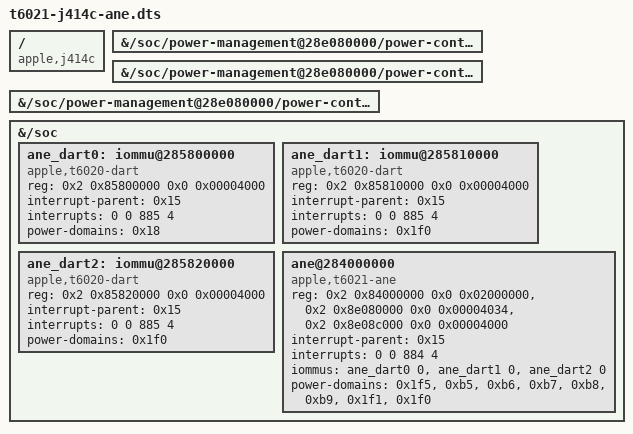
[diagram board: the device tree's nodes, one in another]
// SPDX-License-Identifier: GPL-2.0+ OR MIT
/*
 * Board overlay for jw14m2-linux (J414c / T6021, M2 Max): enable the ANE
 * engine, its three DARTs, and attach the ANE genpd chain the stock DTB
 * already carries (pmgr+0x4000: ane_td@4008 -> ane_base@4010 -> ane_set1..
 * set4@4018-4030, plus ane_cpu@2e0). Applied with fdtoverlay onto the
 * stock modules DTB; boot.bin is rebuilt with update-m1n1.
 *
 * Provenance (receipts 2026-09-18-t6021-engine-layout-mined,
 * 2026-09-18-h14-rtkit-port-phase1, 2026-09-18-h14-w2-protocol-decode):
 *  - ane0 carries its three ADT reg ranges verbatim (raw 0x84000000/
 *    0x8e080000/0x8e08c000, Linux translation +0x200000000, proven pmgr
 *    low-32 class): the WHOLE 32 MiB engine block addressed
 *    block-relative by the W3 skeleton, the pmgr island words, and the
 *    SET window (mapped read-only by the driver; direct SET writes
 *    external-abort). The H13-style engine delta +0x1c04000 does NOT
 *    exist on t6021 — the K14 kext never computes it and first touch at
 *    0x285c2400c external-aborted twice (bisect 2026-09-18); that window
 *    is gone from this overlay.
 *  - dart-ane0 is one ADT node (compatible "dart,t8110" — kernel row is
 *    t8110 per b877b87) with a FOUR-window quartet 0x85800000/85810000/
 *    85820000/85804000, each 0x4000, one mapper, all ANE DMA on it
 *    (ane0 iommu-parent). The installed three-node split (t6001-proven
 *    pattern, b877b87 boot-proven) is kept unchanged; the fourth ADT
 *    window stays unsplit exactly as on T6001.
 *  - IRQs: AIC2 raw 884 (ane) / 885 (dart-ane0), level-high.
 *    [INFERENCE W2 §3] 884 is the ANE ASC mailbox doorbell IRQ the
 *    RTKit transport rides.
 *  - Endpoint/mailbox architecture lives in the driver
 *    (ane/t6021/): ASC cpu block +0x1600000, mailbox +0x1608xxx,
 *    RTKit MGMT handshake, RTBuddy app endpoints 1..6.
 */
/dts-v1/;
/plugin/;

/ {
	compatible = "apple,j414c", "apple,t6021";

	fragment@0 {
		target-path = "/soc/power-management@28e080000/power-controller@2e0";

		__overlay__ {
			phandle = <0x1f0>; /* ane_cpu */
		};
	};

	fragment@1 {
		target-path = "/soc/power-management@28e080000/power-controller@4030";

		__overlay__ {
			phandle = <0x1f1>; /* ane_set4 */
		};
	};

	/* fragment@3: ane_sys_mpm@4000 carries no phandle in the stock DTB
	 * and nothing consumes it, so the set1..4 parent cascade (set4 ->
	 * set3 -> .. -> ane_base@4010 -> ane_td@4008 -> ane_sys@260) can
	 * never raise it. ane0's ADT pmgr window (0x8e080000..+0x4034)
	 * frames exactly this six-island chain, so the bound device must
	 * consume it explicitly. Bisect 2026-09-18: first engine read at
	 * 0x285c2400c external-aborted with the five-domain raise; SET
	 * window at 0x28e08c000 read safe (ACTUALs all zero). Applied at
	 * DTS source level only: fdtoverlay renumbers overlay phandles
	 * without remapping raw refs. */
	fragment@3 {
		target-path = "/soc/power-management@28e080000/power-controller@4000";

		__overlay__ {
			phandle = <0x1f5>; /* ane_sys_mpm */
		};
	};

	/* ane_td@4008 and ane_base@4010 need no fragment: the stock DTB
	 * already gives them phandles (0xb5, 0xb6 — they sit inside the
	 * set1..4 parent cascade). The W3 skeleton consumed only six of
	 * the eight live ANE ps words and the first engine-window read
	 * reset the machine; receipt 2026-09-19-h14-init-sequence-kext-
	 * trace §3 pins the eight-word raise (parent-first, ane_cpu
	 * last) as the proven precondition for any block access. */

	fragment@2 {
		target-path = "/soc";

		__overlay__ {
			#address-cells = <2>;
			#size-cells = <2>;

			ane_dart0: iommu@285800000 {
				compatible = "apple,t6020-dart", "apple,t8110-dart";
				reg = <0x2 0x85800000 0x0 0x00004000>;
				#iommu-cells = <1>;
				interrupt-parent = <0x15>;
				interrupts = <0 0 885 4>;
				power-domains = <0x18>;
				status = "okay";
			};

			ane_dart1: iommu@285810000 {
				compatible = "apple,t6020-dart", "apple,t8110-dart";
				reg = <0x2 0x85810000 0x0 0x00004000>;
				#iommu-cells = <1>;
				interrupt-parent = <0x15>;
				interrupts = <0 0 885 4>;
				power-domains = <0x1f0>;
				status = "okay";
			};

			ane_dart2: iommu@285820000 {
				compatible = "apple,t6020-dart", "apple,t8110-dart";
				reg = <0x2 0x85820000 0x0 0x00004000>;
				#iommu-cells = <1>;
				interrupt-parent = <0x15>;
				interrupts = <0 0 885 4>;
				power-domains = <0x1f0>;
				status = "okay";
			};

			ane@284000000 {
				compatible = "apple,t6021-ane";
				reg-names = "engine", "pmgr", "set";
				reg = <0x2 0x84000000 0x0 0x02000000>,	/* ADT range0, whole block */
				      <0x2 0x8e080000 0x0 0x00004034>,	/* pmgr1,t6021 island words */
				      <0x2 0x8e08c000 0x0 0x00004000>;	/* SET window (reads only) */
				interrupt-parent = <0x15>;
				interrupt-names = "ane";
				interrupts = <0 0 884 4>;
				iommus = <&ane_dart0 0>, <&ane_dart1 0>, <&ane_dart2 0>;
				/* Eight live ANE ps words, phase1 raise
				 * order: parent-first, ane_cpu LAST
				 * (attach order = raise order, each
				 * entry carries DL_FLAG_RPM_ACTIVE). */
				power-domains = <0x1f5>,	/* ane_sys_mpm@4000 */
						<0xb5>,		/* ane_td@4008 */
						<0xb6>,		/* ane_base@4010 */
						<0xb7>,		/* ane_set1@4018 */
						<0xb8>,		/* ane_set2@4020 */
						<0xb9>,		/* ane_set3@4028 */
						<0x1f1>,	/* ane_set4@4030 */
						<0x1f0>;	/* ane_cpu@2e0 (last) */
				status = "okay";
			};
		};
	};
};
